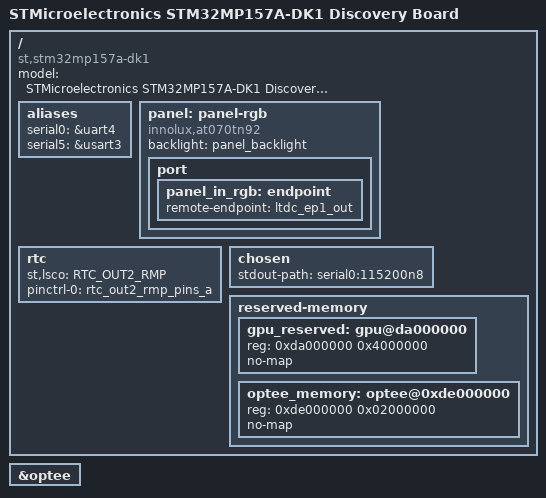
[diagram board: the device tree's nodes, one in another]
// SPDX-License-Identifier: (GPL-2.0+ OR BSD-3-Clause)
/*
 * Copyright (C) STMicroelectronics 2019 - All Rights Reserved
 * Author: Alexandre Torgue <alexandre.torgue@st.com> for STMicroelectronics.
 */

/dts-v1/;

#include "stm32mp157.dtsi"
#include "stm32mp15xa.dtsi"
#include "stm32mp15-pinctrl.dtsi"
#include "stm32mp15xxaa-pinctrl.dtsi"
#include "stm32mp15xx-fsmp1x.dtsi"
/ {
	model = "STMicroelectronics STM32MP157A-DK1 Discovery Board";
	compatible = "st,stm32mp157a-dk1", "st,stm32mp157";

	aliases {
		//ethernet0 = &ethernet0;
		serial0 = &uart4;
		//serial1 = &usart3;
		//serial2 = &uart7;
		serial5 = &usart3;
	};

	panel: panel-rgb {
		compatible = "innolux,at070tn92";
		//compatible = "innolux,at043tn24";
		pinctrl-names = "default", "sleep";
		backlight = <&panel_backlight>;
		status = "okay";
		port {
			panel_in_rgb: endpoint {
				remote-endpoint = <&ltdc_ep1_out>;
			};
		};
	};

	rtc {
		st,lsco = <RTC_OUT2_RMP>;
		pinctrl-0 = <&rtc_out2_rmp_pins_a>;
		pinctrl-names = "default";
		status = "okay";
	};

	chosen {
		stdout-path = "serial0:115200n8";
	};

	reserved-memory {
		gpu_reserved: gpu@da000000 {
			reg = <0xda000000 0x4000000>;
			no-map;
		};

		optee_memory: optee@0xde000000 {
			reg = <0xde000000 0x02000000>;
			no-map;
		};
	};
};

&optee {
	status = "okay";
};
